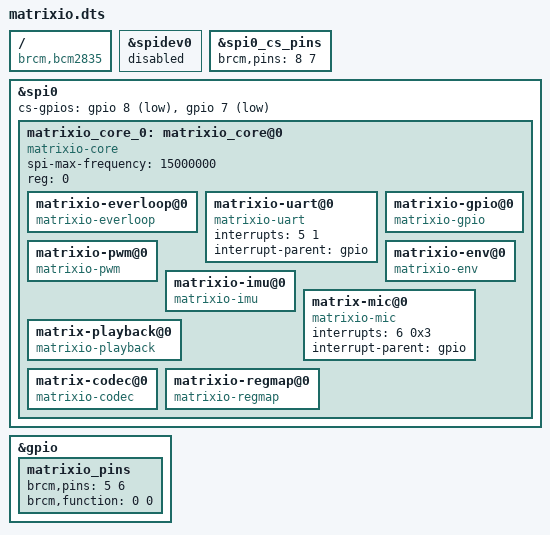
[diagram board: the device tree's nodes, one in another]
/dts-v1/ ;
/plugin/ ;

/ {
	compatible = "brcm,bcm2835", "brcm,bcm2708", "brcm,bcm2709";

	fragment@0 {
		target = <&spidev0>;
		__overlay__ { status = "disabled"; };
	};

	fragment@1 {
		target = <&spi0_cs_pins>;
		frag1: __overlay__ {
			brcm,pins = <8 7>;
		};
	};

	fragment@2 {
		target = <&spi0>;
		frag2: __overlay__ {
			#address-cells = <1>;
			#size-cells = <0>;
			status = "okay";
			cs-gpios = <&gpio 8 1>, <&gpio 7 1>;
 
			matrixio_core_0: matrixio_core@0 {
				compatible = "matrixio-core";
				spi-max-frequency = <15000000>;
				reg = <0>;
			};
		};
	};

	fragment@3 {
		target = <&gpio>;
		__overlay__ {
			matrixio_pins: matrixio_pins {
				brcm,pins = <5 6>;
				brcm,function = <0 0>;
			};
		};
	};


        fragment@4 {
                target = <&matrixio_core_0>;
                __overlay__ {
                        matrixio-everloop@0 {
                                compatible = "matrixio-everloop";

                        };
                };
        };

        fragment@5 {
                target = <&matrixio_core_0>;
                __overlay__ {
                        matrixio-uart@0 {
                                compatible = "matrixio-uart";
				interrupts = <5 1>; /* low-to-high edge triggered */
				interrupt-parent = <&gpio>;
				status = "okay";
                        };
                };
        };

        fragment@6 {
                target = <&matrixio_core_0>;
                __overlay__ {
                        matrixio-gpio@0 {
                                compatible = "matrixio-gpio";
                                status = "okay";
                        };
                };
        };

        fragment@7 {
                target = <&matrixio_core_0>;
                __overlay__ {
                        matrixio-pwm@0 {
                                compatible = "matrixio-pwm";
                                status = "okay";
                        };
                };
        };

	fragment@8 {
		target = <&matrixio_core_0>;
		__overlay__ {
			matrixio-env@0 {
				compatible = "matrixio-env";
				status = "okay";
			};
		};
	};
	fragment@9 {
		target = <&matrixio_core_0>;
		__overlay__ {
			matrixio-imu@0 {
				compatible = "matrixio-imu";
				status = "okay";
			};
		};
	};

        fragment@10 {
                target = <&matrixio_core_0>;
                __overlay__ {
                        matrix-mic@0 {
                                compatible = "matrixio-mic";
                                interrupts = <6 0x3>; /* both edges triggered */
                                interrupt-parent = <&gpio>;
                        };
                };
        };
        fragment@11 {
                target = <&matrixio_core_0>;
                __overlay__ {
                        matrix-playback@0 {
                                compatible = "matrixio-playback";
                        };
                };
        };
        fragment@12 {
                target = <&matrixio_core_0>;
                __overlay__ {
                        matrix-codec@0 {
                                compatible = "matrixio-codec";
                        };
                };
        };

        fragment@13 {
                target = <&matrixio_core_0>;
                __overlay__ {
                        matrixio-regmap@0 {
                                compatible = "matrixio-regmap";

                        };
                };
        };

	__overrides__ {
		cs0_pin  = <&frag1>,"brcm,pins:0",
			   <&frag2>,"cs-gpios:4";
		cs1_pin  = <&frag1>,"brcm,pins:4",
			   <&frag2>,"cs-gpios:16";
	};
};

